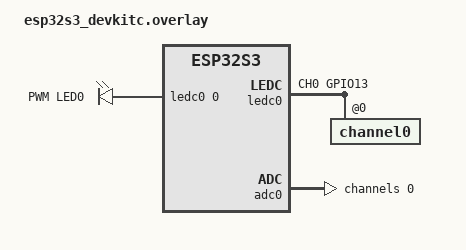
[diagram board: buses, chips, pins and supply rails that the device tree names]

#include <zephyr/dt-bindings/pwm/pwm.h>
/ {
	aliases {
		pwm-0 = &ledc0;
		pwm-led0 = &pwm_led_blue;
        my-adc = &adc0;
        my-adc-channel = &adc0_ch0;
	};

	pwmleds {
		compatible = "pwm-leds";
		pwm_led_blue: pwm_led_gpio0_13 {
			label = "PWM LED0";
			pwms = <&ledc0 0 1000 PWM_POLARITY_NORMAL>;
		};
	};
};

&pinctrl {
	ledc0_default: ledc0_default {
		group1 {
			pinmux = <LEDC_CH0_GPIO13>;
			output-enable;
		};
	};
};

&ledc0 {
	pinctrl-0 = <&ledc0_default>;
	pinctrl-names = "default";
	status = "okay";
	#address-cells = <1>;
	#size-cells = <0>;
	channel0@0 {
		reg = <0x0>;
		timer = <0>;
	};
};


// ADC1 (adc0) channel 0 is connected to GPIO1
&adc0 {
    status = "okay";
    #address-cells = <1>;
    #size-cells = <0>;

    adc0_ch0: channel@0 {
        reg = <0>;
        zephyr,gain = "ADC_GAIN_1_4";
        zephyr,reference = "ADC_REF_INTERNAL";
        zephyr,vref-mv = <3894>;
        zephyr,acquisition-time = <ADC_ACQ_TIME_DEFAULT>;
        zephyr,resolution = <12>;
    };
};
